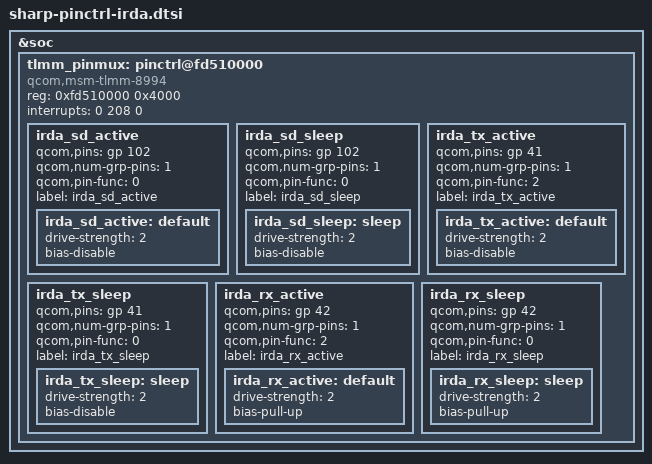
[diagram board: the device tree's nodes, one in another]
/*
 * Copyright (C) 2014 - 2015 SHARP CORPORATION All rights reserved.
 *
 * This software is licensed under the terms of the GNU General Public
 * License version 2, as published by the Free Software Foundation, and
 * may be copied, distributed, and modified under those terms.
 *
 * This program is distributed in the hope that it will be useful,
 * but WITHOUT ANY WARRANTY; without even the implied warranty of
 * MERCHANTABILITY or FITNESS FOR A PARTICULAR PURPOSE.  See the
 * GNU General Public License for more details.
 */

&soc {
	tlmm_pinmux: pinctrl@fd510000 {
		compatible = "qcom,msm-tlmm-8994", "qcom,msm-tlmm-8974";
		reg = <0xfd510000 0x4000>;
		interrupts = <0 208 0>;

		/*****************************************/
		/*  pinctrl customize setting            */
		/*  IrDA                                 */
		/*****************************************/
		
		irda_sd_active {
			qcom,pins = <&gp 102>;
			qcom,num-grp-pins = <1>;
			qcom,pin-func = <0>;
		        label = "irda_sd_active";
			irda_sd_active: default {
				drive-strength = <2>;
				bias-disable;
			};
		};

		irda_sd_sleep {
			qcom,pins = <&gp 102>;
			qcom,num-grp-pins = <1>;
			qcom,pin-func = <0>;
		        label = "irda_sd_sleep";
			irda_sd_sleep: sleep {
				drive-strength = <2>;
				bias-disable;
			};
		};


		irda_tx_active {
			qcom,pins = <&gp 41>;
			qcom,num-grp-pins = <1>;
			qcom,pin-func = <2>;
		        label = "irda_tx_active";
			irda_tx_active: default {
				drive-strength = <2>;
				bias-disable;
			};
		};

		irda_tx_sleep {
			qcom,pins = <&gp 41>;
			qcom,num-grp-pins = <1>;
			qcom,pin-func = <0>;
		        label = "irda_tx_sleep";
			irda_tx_sleep: sleep {
				drive-strength = <2>;
				bias-disable;
			};
		};

		irda_rx_active {
			qcom,pins = <&gp 42>;
			qcom,num-grp-pins = <1>;
			qcom,pin-func = <2>;
		        label = "irda_rx_active";
			irda_rx_active: default {
				drive-strength = <2>;
				bias-pull-up;
			};
		};

		irda_rx_sleep {
			qcom,pins = <&gp 42>;
			qcom,num-grp-pins = <1>;
			qcom,pin-func = <0>;
		        label = "irda_rx_sleep";
			irda_rx_sleep: sleep {
				drive-strength = <2>;
				bias-pull-up;
			};
		};

	};



};
